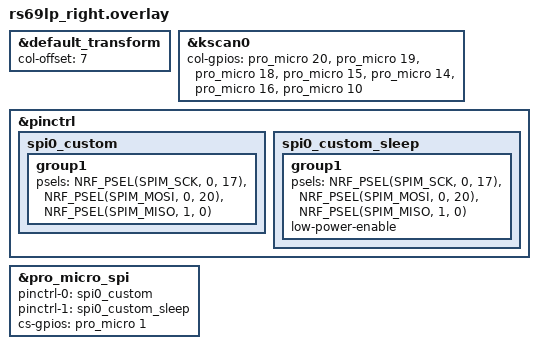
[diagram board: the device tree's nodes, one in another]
// This file was generated from a template. Edit it to match your keyboard.
// See https://zmk.dev/docs/development/hardware-integration/new-shield for more
// instructions.

#include "rs69lp.dtsi"

&default_transform { // The matrix transform for this board is 7 columns over because the left half is 7 columns wide according to the matrix.
    col-offset = <7>;
};

&kscan0 {
    col-gpios
        = <&pro_micro 20 GPIO_ACTIVE_HIGH>
        , <&pro_micro 19 GPIO_ACTIVE_HIGH>
        , <&pro_micro 18 GPIO_ACTIVE_HIGH>
        , <&pro_micro 15 GPIO_ACTIVE_HIGH>
        , <&pro_micro 14 GPIO_ACTIVE_HIGH>
        , <&pro_micro 16 GPIO_ACTIVE_HIGH>
        , <&pro_micro 10 GPIO_ACTIVE_HIGH>
        ;
};


/* Gemini Display remapping code below */
/* --------------------------------------------------------- */
/* PIN SWAP ONLY (Relies on 'nice_view' shield for driver)   */
/* --------------------------------------------------------- */
/* --------------------------------------------------------- */
/* MANUAL PIN SWAP + ADAPTER EMULATION                       */
/* --------------------------------------------------------- */

/* 1. Define the Hardware Pins */
&pinctrl {
    spi0_custom: spi0_custom {
        group1 {
            /* SCK  -> D2 (P0.17) [SWAPPED] */
            psels = <NRF_PSEL(SPIM_SCK, 0, 17)>,
            
            /* MOSI -> D3 (P0.20) [SWAPPED] */
                    <NRF_PSEL(SPIM_MOSI, 0, 20)>,
            
            /* MISO -> P1.00 [Internal Dummy] */
                    <NRF_PSEL(SPIM_MISO, 1, 0)>; 
        };
    };

    spi0_custom_sleep: spi0_custom_sleep {
        group1 {
            psels = <NRF_PSEL(SPIM_SCK, 0, 17)>,
                    <NRF_PSEL(SPIM_MOSI, 0, 20)>,
                    <NRF_PSEL(SPIM_MISO, 1, 0)>;
            low-power-enable;
        };
    };
};

/* 2. Configure the Bus & Provide the MISSING LABEL */
/* The 'nice_view_spi:' label below fixes the build error */

nice_view_spi: &pro_micro_spi {
    status = "okay";
    
    /* Apply our custom pins */
    pinctrl-0 = <&spi0_custom>;
    pinctrl-1 = <&spi0_custom_sleep>;
    pinctrl-names = "default", "sleep";

    /* Define CS on D1 (Required because adapter is gone) */
    cs-gpios = <&pro_micro 1 GPIO_ACTIVE_HIGH>;
};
